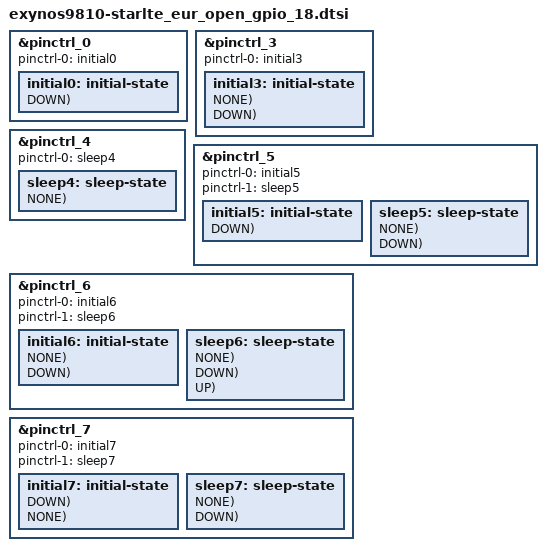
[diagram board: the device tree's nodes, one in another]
/*
 * Copyright (c) 2016 Samsung Electronics Co., Ltd.
 *		http://www.samsung.com
 *
 * This program is free software; you can redistribute it and/or modify
 * it under the terms of the GNU General Public License version 2 as
 * published by the Free Software Foundation.
 */

// Support STAR2 LTE HW REV0.2 (10010)

#include "exynos_gpio_config_macros.dtsi"

/*
 * pin banks of exynos9810 pin-controller 0 (ALIVE)
 * ETC1
 * GPA0 GPA1 GPA2 GPA3
 * GPQ0
 * GPA4
 * Note that do not set sleep state because GPA0/1/2/3/4, GPQ0 and ETC1 are in
 * ALIVE region.
 */
&pinctrl_0 {
	pinctrl-names = "default";
	pinctrl-0 = <&initial0>;
	initial0: initial-state {
		PIN_IN(gpa2-1, DOWN);	/* NC */
		PIN_IN(gpq0-5, DOWN);	/* NC */
	};
};

/*
 * pin banks of exynos9810 pin-controller 3 (CMGP)
 * GPM0 GPM1 GPM2 GPM3 GPM4 GPM5 GPM6 GPM7
 * GPM10 GPM11 GPM12 GPM13 GPM14 GPM15 GPM16 GPM17
 * GPM40 GPM41 GPM42 GPM43
 */
&pinctrl_3 {
	pinctrl-names = "default";
	pinctrl-0 = <&initial3>;
	initial3: initial-state {
		PIN_FUNC(gpm4-0, 2, NONE);	/* SHUB_CP_TXD */
		PIN_FUNC(gpm5-0, 2, NONE);	/* SHUB_CP_RXD */
		PIN_IN(gpm7-0, DOWN);	/* NC */
	};
};

/*
 * pin banks of exynos9810 pin-controller 4 (FSYS0)
 * GPF0
 */
&pinctrl_4 {
	pinctrl-names = "sleep";
	pinctrl-0 = <&sleep4>;
	sleep4: sleep-state {
		PIN_SLP(gpf0-0, PREV, NONE);	/* UFS_REFCLK */
		PIN_SLP(gpf0-1, PREV, NONE);	/* UFS_RST_N */
	};
};

/*
 * pin banks of exynos9810 pin-controller 5 (FSYS1)
 * GPF1 GPF2
 */
&pinctrl_5 {
	pinctrl-names = "default","sleep";
	pinctrl-0 = <&initial5>;
	pinctrl-1 = <&sleep5>;
	initial5: initial-state {
		PIN_IN(gpf1-6, DOWN);	/* NC */
		PIN_IN(gpf2-1, DOWN);	/* NC */
		PIN_IN(gpf2-3, DOWN);	/* NC */
		PIN_IN(gpf2-4, DOWN);	/* NC */
		PIN_IN(gpf2-5, DOWN);	/* NC */
	};
	sleep5: sleep-state {
		PIN_SLP(gpf1-0, OUT0, NONE);		/* SD2_CLK */
		PIN_SLP(gpf1-1, OUT0, NONE);		/* SD2_CMD */
		PIN_SLP(gpf1-2, OUT0, NONE);		/* SD2_DAT0 */
		PIN_SLP(gpf1-3, OUT0, NONE);		/* SD2_DAT1 */
		PIN_SLP(gpf1-4, OUT0, NONE);		/* SD2_DAT2 */
		PIN_SLP(gpf1-5, OUT0, NONE);		/* SD2_DAT3 */
		PIN_SLP(gpf1-6, INPUT, DOWN);	/* NC */
		PIN_SLP(gpf2-0, INPUT, NONE);	/* PCIE_CLK_REQ_L */
		PIN_SLP(gpf2-1, INPUT, DOWN);	/* NC */
		PIN_SLP(gpf2-3, INPUT, DOWN);	/* NC */
		PIN_SLP(gpf2-4, INPUT, DOWN);	/* NC */
		PIN_SLP(gpf2-5, INPUT, DOWN);	/* NC */
	};
};

/*
 * pin banks of exynos9810 pin-controller 6 (PERIC0)
 * GPP0 GPP1 GPP2 GPP3
 * GPG0 GPG1 GPG2
 */
&pinctrl_6 {
	pinctrl-names = "default","sleep";
	pinctrl-0 = <&initial6>;
	pinctrl-1 = <&sleep6>;
	initial6: initial-state {
		PIN_IN(gpp2-4, NONE);	/* MEM_SCL_1P8 */
		PIN_IN(gpp2-5, NONE);	/* MEM_SDA_1P8 */
		PIN_IN(gpp2-6, DOWN);	/* NC */
		PIN_IN(gpp2-7, DOWN);	/* NC */

		PIN_IN(gpg0-6, DOWN);	/* NC */

		PIN_IN(gpg2-7, DOWN);	/* NC */

		PIN_IN(gpg1-1, NONE);	/* HW_REV_M */
		PIN_IN(gpg1-2, NONE);	/* HW_REV3 */
		PIN_IN(gpg1-3, NONE);	/* HW_REV2 */
		PIN_IN(gpg1-4, NONE);	/* HW_REV1 */
		PIN_IN(gpg1-5, NONE);	/* HW_REV0 */

		PIN_IN(gpg2-3, DOWN);	/* IRIS_RST_N */
	};
	sleep6:sleep-state {
		PIN_SLP(gpp0-0, OUT0, NONE);	/* BTP_SPI_CLK */
		PIN_SLP(gpp0-1, OUT0, NONE);	/* BTP_SPI_MOSI */
		PIN_SLP(gpp0-2, INPUT, DOWN);	/* BTP_SPI_MISO */
		PIN_SLP(gpp0-3, OUT0, NONE);	/* BTP_SPI_CS_N */

		PIN_SLP(gpp1-4, PREV, NONE);	/* TSP_SCL_1P8 */
		PIN_SLP(gpp1-5, PREV, NONE);	/* TSP_SDA_1P8 */
		PIN_SLP(gpp1-6, INPUT, NONE);	/* GRIP_SCL_1P8 */
		PIN_SLP(gpp1-7, INPUT, NONE);	/* GRIP_SDA_1P8 */

		PIN_SLP(gpp2-4, INPUT, NONE);	/* MEM_SCL_1P8 */
		PIN_SLP(gpp2-5, INPUT, NONE);	/* MEM_SDA_1P8 */
		PIN_SLP(gpp2-6, INPUT, DOWN);	/* NC */
		PIN_SLP(gpp2-7, INPUT, DOWN);	/* NC */

		PIN_SLP(gpg0-0, INPUT, UP);	/* IFC_SENSE_INT_AP */
		PIN_SLP(gpg0-4, INPUT, UP);	/* USB3.1_CON_SEL */
		PIN_SLP(gpg0-5, PREV, NONE);	/* WLAN_EN */
		PIN_SLP(gpg0-6, INPUT, DOWN);	/* NC */

		PIN_SLP(gpg0-3, INPUT, NONE);	/* SMPL_WARN_AP */

		PIN_SLP(gpg1-1, INPUT, NONE);	/* HW_REV_M */
		PIN_SLP(gpg1-2, INPUT, NONE);	/* HW_REV3 */
		PIN_SLP(gpg1-3, INPUT, NONE);	/* HW_REV2 */
		PIN_SLP(gpg1-4, INPUT, NONE);	/* HW_REV1 */
		PIN_SLP(gpg1-5, INPUT, NONE);	/* HW_REV0 */

		PIN_SLP(gpg2-1, INPUT, NONE);	/* SUB_PMIC_IRQ_N */
		PIN_SLP(gpg2-2, PREV, NONE);	/* DISP_DET */
		PIN_SLP(gpg2-4, PREV, DOWN);	/* CAM_TORCH_EN */
		PIN_SLP(gpg2-6, OUT0, DOWN);	/* CAM_RST_N */
		PIN_SLP(gpg2-7, INPUT, DOWN);	/* NC */
	};
};

/*
 * pin banks of exynos9810 pin-controller 7 (PERIC1)
 * GPP4 GPP5 GPP6
 * GPC0 GPC1
 * GPD0
 * GPG3
 */
&pinctrl_7 {
	pinctrl-names = "default","sleep";
	pinctrl-0 = <&initial7>;
	pinctrl-1 = <&sleep7>;
	initial7: initial-state {
		PIN_IN(gpc0-4, DOWN);	/* NC */
		PIN_IN(gpc0-5, DOWN);	/* NC */
		PIN_IN(gpc0-6, DOWN);	/* NC */
		PIN_IN(gpc0-7, DOWN);	/* NC */

		PIN_IN(gpc1-7, DOWN);	/* NC */

		PIN_IN(gpd0-1, DOWN);	/* NC */
		PIN_IN(gpd0-3, DOWN);	/* NC */

		PIN_IN(gpg3-0, NONE);	/* CP_REV3 */
		PIN_IN(gpg3-1, NONE);	/* CP_REV2 */
		PIN_IN(gpg3-2, NONE);	/* CP_REV1 */
		PIN_IN(gpg3-3, NONE);	/* CP_REV0 */
	};
	sleep7:sleep-state {
		PIN_SLP(gpp5-0, INPUT, NONE);	/* NFC_HRM_SCL_1P8 */
		PIN_SLP(gpp5-1, INPUT, NONE);	/* NFC_HRM_SDA_1P8 */

		PIN_SLP(gpp6-0, INPUT, NONE);	/* SUB_PMIC_SCL_1P8 */
		PIN_SLP(gpp6-1, INPUT, NONE);	/* SUB_PMIC_SDA_1P8 */
		PIN_SLP(gpp6-2, INPUT, NONE);	/* EXPANDER_SCL_1P8 */
		PIN_SLP(gpp6-3, INPUT, NONE);	/* EXPANDER_SDA_1P8 */

		PIN_SLP(gpc0-0, INPUT, NONE);	/* CAM_SCL_1P8 */
		PIN_SLP(gpc0-1, INPUT, NONE);	/* CAM_SDA_1P8 */
		PIN_SLP(gpc0-4, INPUT, DOWN);	/* NC */
		PIN_SLP(gpc0-5, INPUT, DOWN);	/* NC */
		PIN_SLP(gpc0-6, INPUT, DOWN);	/* NC */
		PIN_SLP(gpc0-7, INPUT, DOWN);	/* NC */

		PIN_SLP(gpc1-7, INPUT, DOWN);	/* NC */

		PIN_SLP(gpd0-0, PREV, NONE);	/* DISP_TE */
		PIN_SLP(gpd0-1, INPUT, DOWN);	/* NC */
		PIN_SLP(gpd0-2, OUT0, NONE);		/* XBOOTLDO0 */
		PIN_SLP(gpd0-3, INPUT, DOWN);	/* NC */

		PIN_SLP(gpg3-0, INPUT, NONE);	/* CP_REV3 */
		PIN_SLP(gpg3-1, INPUT, NONE);	/* CP_REV2 */
		PIN_SLP(gpg3-2, INPUT, NONE);	/* CP_REV1 */
		PIN_SLP(gpg3-3, INPUT, NONE);	/* CP_REV0 */
		PIN_SLP(gpg3-4, OUT0, DOWN);	/* MST_PWR_EN */
		PIN_SLP(gpg3-5, OUT0, DOWN);	/* CAM_FLASH_EN */
	};
};
